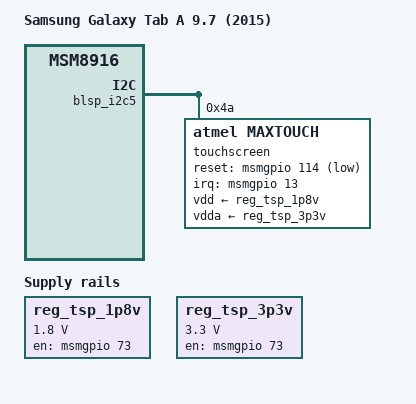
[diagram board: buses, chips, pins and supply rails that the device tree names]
// SPDX-License-Identifier: GPL-2.0-only

/dts-v1/;

#include "msm8916-samsung-gt5-common.dtsi"

/ {
	model = "Samsung Galaxy Tab A 9.7 (2015)";
	compatible = "samsung,gt510", "qcom,msm8916";

	reg_tsp_1p8v: regulator-tsp-1p8v {
		compatible = "regulator-fixed";
		regulator-name = "tsp_1p8v";
		regulator-min-microvolt = <1800000>;
		regulator-max-microvolt = <1800000>;

		gpio = <&msmgpio 73 GPIO_ACTIVE_HIGH>;
		enable-active-high;

		pinctrl-names = "default";
		pinctrl-0 = <&tsp_en_default>;
	};

	reg_tsp_3p3v: regulator-tsp-3p3v {
		compatible = "regulator-fixed";
		regulator-name = "tsp_3p3v";
		regulator-min-microvolt = <3300000>;
		regulator-max-microvolt = <3300000>;

		gpio = <&msmgpio 73 GPIO_ACTIVE_HIGH>;
		enable-active-high;
	};
};

&blsp_i2c5 {
	status = "okay";

	touchscreen@4a {
		compatible = "atmel,maxtouch";
		reg = <0x4a>;
		interrupt-parent = <&msmgpio>;
		interrupts = <13 IRQ_TYPE_EDGE_FALLING>;

		vdd-supply = <&reg_tsp_1p8v>;
		vdda-supply = <&reg_tsp_3p3v>;

		reset-gpios = <&msmgpio 114 GPIO_ACTIVE_LOW>;

		pinctrl-names = "default";
		pinctrl-0 = <&tsp_int_rst_default>;
	};
};

&msmgpio {
	tsp_en_default: tsp-en-default {
		pins = "gpio73";
		function = "gpio";

		drive-strength = <2>;
		bias-disable;
	};

	tsp_int_rst_default: tsp-int-rst-default {
		pins = "gpio13", "gpio114";
		function = "gpio";

		drive-strength = <2>;
		bias-disable;
	};
};
